# MSS_MIBSPIA register map
Vendor: Texas Instruments
Peripheral module from a debugger description file (folder radar).
Registers are 32-bit, access per field, no defined reset value unless marked. A register's access mark holds for its fields unless they carry their own. Offsets are as the file gives them; lines under a group give offsets from that group; [hi:lo] are bit positions; {n}, {i} and the like mark numbered series; 'fields as' and 'values as' point back to an identical list; <NAME> marks a mode.

## MSS_MIBSPIA (part 1 of 4)
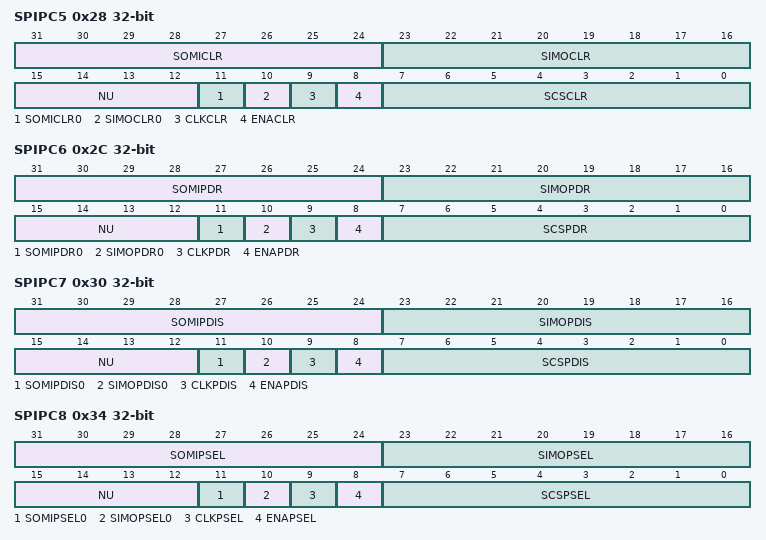
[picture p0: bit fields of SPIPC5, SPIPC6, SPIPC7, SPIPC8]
0x28 SPIPC5 — SPI / MibSPI Pin Control Register 5 (SPIPC5) - SPIDCLR
  [31:24] SOMICLR rw — SPISOMIx dataout clear. Only active when the SPISOMIx pin is configured as a general-purpose output pin. A value of ‘1’ written to this bit clears the corresponding SPISOMIDOUTx bit to ‘0’. Write: 0= Has no effect 1= Logic 0 placed on SPISOMIx pin if it is in General Purpose O/P mode Read: 0= Current value on SOMIDOUTx is 0. 1= Current value on SOMIDOUTx is 1.
  [23:16] SIMOCLR rw — SPISIMOx dataout clear. Only active when the SPISIMOx pin is configured as a general-purpose output pin. A value of ‘1’ written to this bit clears the corresponding SPISIMODOUTx bit to ‘0’. Write: 0= Has no effect 1= Logic 0 placed on SPISIMOx pin if it is in General Purpose O/P mode Read: 0=Current value on SIMODOUTx is 0. 1=Current value on SIMODOUTx is 1.
  [15:12] NU ro — Reserved. Reads return ‘0’ and writes have no effect.
  [11] SOMICLR0 rw — SPISOMI0 dataout clear. Only active when the SPISOMI0 pin is configured as a general-purpose output pin. A value of ‘1’ written to this bit clears the corresponding SPISOMIDOUT bit to ‘0’. Write: 0= Has no effect 1= Logic 0 placed on SPISOMI0 pin if it is in General Purpose O/P mode Read: 0= Current value on SOMIDOUT0 is 0. 1= Current value on SOMIDOUT0 is 1. Note: Bit 11 or bit 24 can be used to set the direction for pin SOMI0. If a 32 bit write is performed, bit 11 will have priority over bit 24.
  [10] SIMOCLR0 rw — SPISIMO0 dataout clear. Only active when the SPISIMO0 pin is configured as a general-purpose output pin. A value of ‘1’ written to this bit clears the corresponding SIMODOUT0 bit to ‘0’. Write: 0= Has no effect 1= Logic 0 placed on SPISIMO0 pin if it is in General Purpose O/P mode Read: 0= Current value on SIMODOUT0 is 0. 1= Current value on SIMODOUT0 is 1. Note: Bit 10 or bit 16 can be used to set the direction for pin SIMO0. If a 32 bit write is performed, bit 10 will have priority over bit 16.
  [9] CLKCLR rw — SPICLK dataout clear. Only active when the SPICLK pin is configured as a general-purpose output pin. A value of ‘1’ written to this bit clears the corresponding CLKDOUT bit to ‘0’. Write: 0= Has no effect 1= Logic 0 placed on SPICLK pin if it is in General Purpose O/P mode Read: 0= Current value on CLKDOUT is 0. 1= Current value on CLKDOUT is 1.
  [8] ENACLR rw — SPIENA dataout clear. Only active when the SPIENA pin is configured as a general-purpose output pin. A value of ‘1’ written to this bit clears the corresponding ENABLEDOUT bit to ‘0’. Write: 0= Has no effect 1= Logic 0 placed on SPIENA pin if it is in General Purpose O/P mode Read: 0= Current value on ENADOUT is 0. 1= Current value on ENADOUT is 1.
  [7:0] SCSCLR rw — SPISCS[7:0] dataout clear. Only active when the SPISCSx pins are configured as a general-purpose output pins. A value of ‘1’ written to this bit clears the corresponding SCSDOUT bit to ‘0.. Write: 0= Has no effect 1= Logic 0 placed on SPISCSx pin if it is in General Purpose O/P mode Read: 0= Current value on SCSDOUTx is 0. 1= Current value on SCSDOUTx is 1 Note: Effect of NUM_CS_PINS generic on ChipSelect bits. Actual number of bits implemented in SCSCLR[7:0] will depend upon the NUM_CS_PINS generic set during synthesis. Unimplemented bits will be read-only and will read ‘0’ always. Note: Register Read Read of SPIPC5 register gives out contents of the SPIPC3 register.
0x2C SPIPC6 — SPI / MibSPI Pin Control Register 6 (SPIPC6) - SPIPDR
  [31:24] SOMIPDR rw — SPISOMIx Open drain enable Enables Open drain capability for the pin SOMIx if the following conditions are met. SOMIDIRx = 1 (SPISOMI0 pin configured in GPIO mode as output pin) SOMIDOUTx = 1 0 = Output value on SPISOMIx pin is logic ‘1’ 1 = Output pin SPISOMIx is Tri-stated
  [23:16] SIMOPDR rw — SPISIMOx Open drain enable Enables Open drain capability for the pin SPISIMOx if the following conditions are met. SIMODIRx = 1 (SPISIMOx pin configured in GPIO mode as output pin) SIMODOUTx = 1 0 = Output value on SPISIMOx pin is logic ‘1’ 1 = Output pin SPISIMOx is Tri-stated
  [15:12] NU ro — Reserved. Reads return ‘0’ and writes have no effect.
  [11] SOMIPDR0 rw — SPISOMI0 Open drain enable Enables Open drain capability for the pin SPISOMI if the following conditions are met. SOMIDIR0 = 1 (SPISOMI0 pin configured in GPIO mode as output pin) SOMIDOUT0 = 1 0 = Output value on SPISOMI0 pin is logic ‘1’ 1 = Output pin SPISOMI0 is Tri-stated Note: Bit 11 or bit 24 can be used to set the direction for pin SPISOMI0. If a 32 bit write is performed, bit 11 will have priority over bit 24.
  [10] SIMOPDR0 rw — SPISIMO0 Open drain enable Enables Open drain capability for the pin SPISIMO0 if the following conditions are met. SIMODIR0 = 1 (SPISIMO pin configured in GPIO mode as output pin) SIMODOUT0 = 1 0 = Output value on SPISIMO0 pin is logic ‘1’ 1 = Output pin SPISIMO0 is Tri-stated Note: Bit 10 or bit 16 can be used to set the direction for pin SPISIMO0. If a 32 bit write is performed, bit 10 will have priority over bit 16.
  [9] CLKPDR rw — SPICLK Open drain enable Enables Open drain capability for the pin CLK if the following conditions are met. CLKDIR = 1 (SPICLK pin configured in GPIO mode as output pin) CLKDOUT = 1 0 = Output value on SPICLK pin is logic ‘1’ 1 = Output pin SPICLK is Tri-stated
  [8] ENAPDR rw — SPIENA Open drain enable Enables Open drain capability for the pin SPIENA if the following conditions are met. ENABLEDIR = 1 (SPIENA pin configured in GPIO mode as output pin) ENABLEDOUT = 1 0 = Output value on SPIENA pin is logic ‘1’ 1 = Output pin SPIENA is Tri-stated
  [7:0] SCSPDR rw — SPISCSx Open drain enable Enables Open drain capability for the pin SPISCSx if the following conditions are met. SCSDIRx = 1 (SPISCS pin configured in GPIO mode as output pin) SCSDOUTx = 1 0 = Output value on SPISCSx pin is logic ‘1’ 1 = Output pin SPISCSx is Tri-stated Note: Effect of NUM_CS_PINS generic on ChipSelect bits. Actual number of bits implemented in SCSPDR[7:0] will depend upon the NUM_CS_PINS generic set during synthesis. Unimplemented bits will be read-only and will read ‘0’ always.
0x30 SPIPC7 — SPI / MibSPI Pin Control Register 7 (SPIPC7) - SPIPDIS Note: Default Register Value. The default values of the register bits are determined by the value at the port PULDIS_TIEOFF on the SPI/MibSPI entity. This port needs to be tied-off during device integration. Default value will be same as the value of PULDIS_TIEOFF port.
  [31:24] SOMIPDIS rw — SPISOMIx Pull Control enable/disable Enables Pull Control capability for the pin SPISOMIx pin if it is in input mode irrespective of whether it is in Functional or GPIO mode. 0 = Pull control on SPISOMIx pin is enabled 1 = Pull control on SPISOMIx pin is disabled
  [23:16] SIMOPDIS rw — SPISIMOx Pull Control enable/disable Enables Pull Control capability for the pin SPISIMOx pin if it is in input mode irrespective of whether it is in Functional or GPIO mode. 0 = Pull control on SPISIMOx pin is enabled 1 = Pull control on SPISIMOx pin is disabled
  [15:12] NU ro — Reserved. Reads return ‘0’ and writes have no effect.
  [11] SOMIPDIS0 rw — SPISOMI0 Pull Control enable/disable Enables Pull Control capability for the pin SPISOMI0x pin if it is in input mode irrespective of whether it is in Functional or GPIO mode. 0 = Pull control on SPISOMI0 pin is enabled 1 = Pull control on SPISOMI0 pin is disabled Note: Bit 11 or bit 24 can be used to set the direction for pin SPISOMI0. If a 32 bit write is performed, bit 11 will have priority over bit 24.
  [10] SIMOPDIS0 rw — SPISIMO Pull Control enable/disable Enables Pull Control capability for the pin SPISIMO0x pin if it is in input mode irrespective of whether it is in Functional or GPIO mode. 0 = Pull control on SPISIMO0 pin is enabled 1 = Pull control on SPISIMO0 pin is disabled Note: Bit 10 or bit 16 can be used to set the direction for pin SPISIMO0. If a 32 bit write is performed, bit 10 will have priority over bit 16.
  [9] CLKPDIS rw — SPICLK Pull Control enable/disable Enables Pull Control capability for the pin SPICLK pin if it is in input mode irrespective of whether it is in Functional or GPIO mode. 0 = Pull control on SPICLK pin is enabled 1 = Pull control on SPICLK pin is disabled
  [8] ENAPDIS rw — SPIENA Pull Control enable/disable Enables Pull Control capability for the pin SPIENA pin if it is in input mode irrespective of whether it is in Functional or GPIO mode. 0 = Pull control on SPIENA pin is enabled 1 = Pull control on SPIENA pin is disabled
  [7:0] SCSPDIS rw — SPISCSx Pull Control enable/disable Enables Pull Control capability for the pin SPISCSx pin if it is in input mode irrespective of whether it is in Functional or GPIO mode. 0 = Pull control on SPISCSx pin is enabled 1 = Pull control on SPISCSx pin is disabled Note: Effect of NUM_CS_PINS generic on ChipSelect bits. Actual number of bits implemented in SCSPDIS[7:0] will depend upon the NUM_CS_PINS generic set during synthesis. Unimplemented bits will be read-only and will read ‘0’ always.
0x34 SPIPC8 — SPI / MibSPI Pin Control Register 8 (SPIPC8) - SPIPSEL Note: Default Register Value. The default values of this register bits are determined by the value at the port PULDIS_TIEOFF on the SPI/MibSPI entity. This port needs to be tied-off during device integration. The default value will be the inverted value of PULDIS_TIEOFF port.
  [31:24] SOMIPSEL rw — SPISOMIx Pull Select Selects type of pull logic at the SPISOMIx pin. 0 = Pull down on SPISOMIx pin 1 = Pull up on SPISOMIx pin
  [23:16] SIMOPSEL rw — SPISIMOx Pull Select Selects type of pull logic at the SPISIMOx pin. 0 = Pull down on SPISIMOx pin 1 = Pull up on SPISIMOx pin
  [15:12] NU ro — Reserved. Reads return ‘0’ and writes have no effect.
  [11] SOMIPSEL0 rw — SPISOMI Pull Select Selects type of pull logic at the SPISOMI pin. 0 = Pull down on SPISOMI pin 1 = Pull up on SPISOMI pin Note: Bit 11 or bit 24 can be used to set the direction for pin SPISOMI0. If a 32 bit write is performed, bit 11 will have priority over bit 24.
  [10] SIMOPSEL0 rw — SPISIMO Pull Select Selects type of pull logic at the SPISIMO pin. 0 = Pull down on SPISIMO pin 1 = Pull up on SPISIMO pin Note: Bit 10 or bit 16 can be used to set the direction for pin SPISIMO0. If a 32 bit write is performed, bit 10 will have priority over bit 16.
  [9] CLKPSEL rw — SPICLK Pull Select Selects type of pull logic at the SPICLK pin. 0 = Pull down on SPICLK pin 1 = Pull up on SPICLK pin
  [8] ENAPSEL rw — SPIENA Pull select Selects type of pull logic at the SPIENA pin. 0 = Pull down on SPIENA pin. 1 = Pull up on SPIENA pin.
  [7:0] SCSPSEL rw — SPISCSx Pull select Selects type of pull logic at the SPISCSx pin. 0 = Pull down on SPISCSx. 1 = Pull up on SPISCSx pin. Note: Effect of NUM_CS_PINS generic on ChipSelect bits. Actual number of bits implemented in SCSPSEL[7:0] will depend upon the NUM_CS_PINS generic set during synthesis. Unimplemented bits will be read-only and will read ‘0’ always.
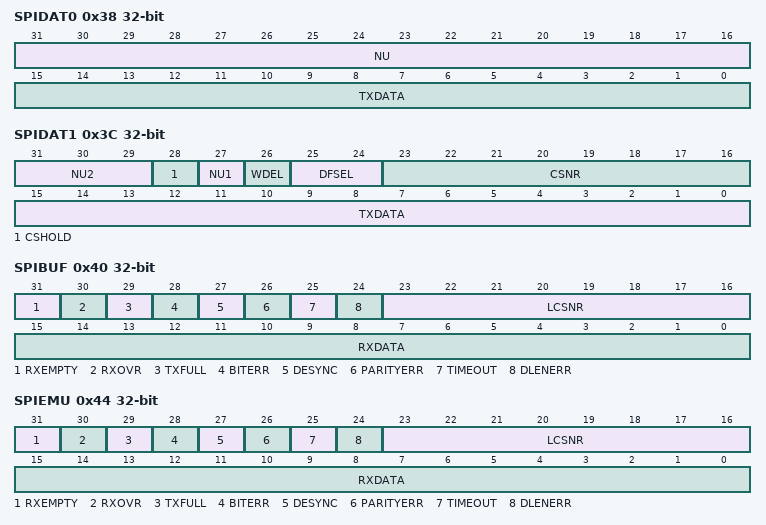
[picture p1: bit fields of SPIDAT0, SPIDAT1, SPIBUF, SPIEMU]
0x38 SPIDAT0 — SPI / MibSPI Transmit Data Register 0 Note: Accessibility of SPIDAT0 The SPIDAT0 register is not accessible in Multibuffer Mode of MibSPI. It is only accessible in compatibility mode.
  [31:16] NU ro — Reserved. Reads return ‘0’ and writes have no effect.
  [15:0] TXDATA rw — SPI / MibSPI Transmit Data. When written, these bits will be copied to the Shift Register if it is empty. If the Shift Register is not empty, the TXBUF will hold the written values. SPIEN (SPICGR1.24) must be set to 1 before this register can be written to. Writing a 0 to the SPIEN register forces the lower 16 bits of the SPIDAT0 register to 0x00. When this register is read, contents of internal buffer register TXBUF which holds the latest written data will be returned. As the data is shifted out from either the MSB or the LSB of Transmit Shift Register depending upon SHIFTDIR bit (SPIFMTx.20). Simultaneously, the received bit will be shifted into the Receive Shift Register either through LSB or MSB depending upon SHIFTDIR bit. This allows the concurrent transmission and reception of data. Note: Irrespective of the character length, the Transmit data should be right justified before writing to SPIDAT0 register. The default Data Format Control register for SPIDAT0 is SPIFMT0. However it is possible to reprogram the DFSEL[1:0] fields of SPIDAT1 prior to using SPIDAT0, to select a different SPIFMTx register.
0x3C SPIDAT1 — SPI / MibSPI Transmit Data Register 1 When this register is read, contents of internal buffer register TXBUF which holds the latest written data will be returned.
  [31:29] NU2 ro — Reserved. Reads return ‘0’ and writes have no effect.
  [28] CSHOLD rw — Chip select hold mode. In SPI or compatibility mode MibSPI, the CSHOLD bit is supported in master mode only. In slave mode, this bit is ignored. CSHOLD defines the behavior of the chip select line at the end of a data transfer. 1 =The chip select signal is held active at the end of a transfer until a control field with new data and control information is loaded into SPIDAT1. If the new chip select information equals the previous one, the active chip select signal is extended until the end of transfer with CSHOLD cleared or until the chip select information changes. 0 =The chip select signal is deactivated at the end of a transfer after the T2CDELAY time has passed. If two consecutive transfers are dedicated to the same chip select this chip select signal will be deactivated for atleast 2VCLK cycles before it is activated again.
  [27] NU1 ro — Reserved. Reads return ‘0’ and writes have no effect.
  [26] WDEL rw — Enable the delay counter at the end of the current transaction. WDELAY bit is supported in Master mode only. In Slave mode, this bit will be ignored. 1 = After a transaction, WDELAY of the corresponding data format will be loaded into the delay counter. No transaction will be performed until the WDELAY counter overflows. The SPISCS pins will be de-activated for atleast (WDELAY + 2) * VCLK_Period duration. 0 = No delay will be inserted. However, SPISCS pins will still be de-activated for atleast for 2VCLK cycles if CSHOLD = ‘0’. In SPI or Compatibility mode of MibSPI, the duration for which the SPISCS pin remaining de-activated will also depend upon time taken to supply a new data after completing the shifting operation. If the internal buffer - TXBUF is already full, then the SPISCS will be deasserted for atleast 2 VCLK cycles(if WDEL = ‘0’).
  [25:24] DFSEL rw — DFSEL1 DFSEL0 Description 0 0 Data word format 0 is selected 0 1 Data word format 1 is selected 1 0 Data word format 2 is selected 1 1 Data word format 3 is selected
  [23:16] CSNR rw — Chip select number. CSNR defines the chip select that shall be activated during the data transfer. The value of CSNR[7:0] will be driven on SPISCS[7:0] lines during the transfer. Note: Effect of NUM_CS_PINS generic on CSNR bits. Actual number of bits implemented in CSNR[7:0] will depend upon the NUM_CS_PINS generic set during synthesis. Unimplemented bits will be read-only and will read ‘0’ always. Note: Preselecting a Format Register. Writing to just the Control Field (using byte writes) does not initiate any SPI transfer in Master mode. This feature can be used to setup SPICLK Phase or Polarity before actually starting the transfer by just updating the DFSEL fields in the control field to select the required Phase/Polarity combination.
  [15:0] TXDATA rw — SPI / MibSPI Transmit Data. When written, these bits will be copied to the Shift Register if it is empty. If the Shift Register is not empty, the TXBUF will hold the written values. SPIEN must be set to 1 before this register can be written to. Writing a 0 to the SPIEN register forces the lower 16 bits of the SPIDAT1 register to 0x00. Write to this register ONLY when using the automatic Slave Chip Select feature. See section 3, Operation Modes, on page 14. A write to this register will drive the contents of CSNR[7:0] into the respective pins in SPISCS[7:0] if those are configured as functional pins. When this register is read, contents of internal buffer register TXBUF which holds the latest written data will be returned. Irrespective of the character length, the Transmit data should be right justified before writing to SPIDAT1 register.
0x40 SPIBUF access not given — SPI / MibSPI Receive Buffer Register
  [31] RXEMPTY — Receive data buffer empty. When host reads the SPIBUF field or the whole SPIBUF register this will automatically set the RXEMPTY flag. When a data transfer is completed, the received data is copied into SPIBUF, the RXEMPTY flag is cleared. 1 =No data received since last reading of SPIBUF register. 0 =A new Data is received and copied into SPIBUF field. This flag gets set to ‘1’ under following conditions: oReading RXDATA portion of the SPIBUF register. oWriting ‘1’ to clear the RXINTFLG bit in SPIFLG register. Write-Clearing the RXINTFLG bit before reading the SPIBUF indicates the received data is being ignored. Conversely, RXINTFLG can be cleared by reading the RXDATA portion of the SPIBUF register. So, reading the full of SPIBUF register itself clears the Receiver Full Interrupt Flag.
  [30] RXOVR — Receive data buffer overrun. When a data transfer is completed and the received data is copied into the RXBUF while it is already full, RXOVR is set. Refer to Figure 1 for a view of internal logic diagram. An Overrun always occurs to the RXBUF, and SPIBUF contents never get Overwritten until after it is read by the VBUSP Master. If enabled, RXOVRN interrupt gets generated when RXBUF is Overwritten, and reading SPIFLG or SPIVECTx register shows the RXOVRN condition. However, two read operations to the SPIBUF register are required to reach the Overrun buffer. 1 =A receive data overrun condition occurred since last time reading the data field. 0 =No receive data overrun condition occurred since last time reading the data field. This bit is cleared to ‘0’ under the following conditions: o RXDATA portion of the SPIBUF register is read. o OVRNINTFLG bit in SPIFLG register is write-cleared. When an Overrun occurs, the SPIBUF contents will not be overwritten. Only the RXBUF contents are overwritten. When the SPIBUF is read out , the RXBUF contents get copied to the SPIBUF if RXBUF is full. So, the first data read out will be intact when an Overrun occurs. Note: A special condition under which RXOVR flag gets set. If both SPIBUF & RXBUF are already full and while another buffer receive is underway, if any errors like TIMEOUT, BITERR & DLEN_ERR occur, then RXOVR in RXBUF & SPIFLG registers will be set to indicate that the status flags are getting overwritten by the new transfer. This overrun should be treated like a normal Receiver Overrun.
  [29] TXFULL ro — Transmit data buffer full. This flag is a read-only flag. Writing into SPIDAT0 or SPIDAT1 field while TX Shift Register is full will automatically set the TXFULL flag. Once the data is copied to the Shift Register the TXFULL flag will be cleared. Writing to SPIDAT0/SPIDAT1 register when both TXBUF & the TX Shift Register are empty does not set the TXFULL flag. 1 =Transmit buffer is full, SPIDAT0/SPIDAT1 is not ready to accept a new data. 0 =Transmit buffer is empty, SPIDAT0/SPIDAT1 is ready to accept a new data.
  [28] BITERR — Mismatch of internal transmit data and transmitted data. 1 =A bit error occurred. The SPI / MibSPI samples the signal of the transmit pin (master: SIMO, slave: SOMI) at the receive point (half clock cycle after transmit point). If the sampled value differs from the transmitted value a bit error is detected and the flag BITERR is set. A possible reason for a bit error can be noise, a to high bit rate / capacitive load or another master/slave trying to transmit at the same time. 0 =No bit error occurred. This flag is cleared to ‘0’ when RXDATA portion of the SPIBUF register is read.
  [27] DESYNC — De-synchronization of slave device. De-synchronization monitor is active in master mode only. 1 =A slave device is de-synchronized. The master monitors the ENA signal coming from the slave device and sets the DESYNC flag if ENA is deactivated before the last reception point or after the last bit is transmitted plus tT2EDELAY (see Section 8.21). If DESYNCENA is set an interrupt is asserted. De-synchronization can occur if a slave device misses a clock edge coming from the master. 0 =No slave de-synchronization detected. This bit is valid in Master mode only. This flag is cleared to ‘0’ when RXDATA portion of the SPIBUF register is read. Note: Possible inconsistency of Desync flag in SPI/Compatibility mode MibSPI Due to the nature of this Error, under some circumstances it is possible for Desync error detected for the previous buffer to be visible in the current buffer. This is due to the fact that Receive Completion flag/interrupt will be generated when the buffer transfer is completed. But Desync will be detected after the buffer transfer is completed. So, if VBUS master reads the received data quickly when an RXINT is detected, then the status flag may not reflect the correct Desync condition. This inconsistency in Desync flag is valid only in SPI or Compatibility mode of MibSPI. In Multibuffer mode, Desync flag is always guaranteed to be for the current buffer.
  [26] PARITYERR — Calculated parity differs from received parity bit. 1 =A parity error occurred. If the parity generator is enabled (can be selected individually for each buffer) an even or odd parity bit is added at the end of a data word (see Section 8.23). During reception of the data word the parity generator calculates the reference parity and compares it to the received parity bit. In the event of a mismatch the PARITYERR flag is set. 0 =No parity error detected. This flag is cleared to ‘0’ when RXDATA portion of the SPIBUF register is read.
  [25] TIMEOUT — Time-out due to non-activation of ENA pin. 1 =An ENA signal time-out occurred. The SPI / MibSPI generates a time-out because the slave hasn’t responded in time by activating the ENA signal after the chip select signal has been activated. If a time-out condition is detected the corresponding chip select is deactivated immediately and the TIMEOUT flag is set. In addition the TIMOUT flag in the status field of the corresponding buffer and in the SPIFLG register is set. 0 =No ENA-pin time-out occurred. This flag is cleared to ‘0’ when RXDATA portion of the SPIBUF register is read. This bit is valid in Master mode only.
  [24] DLENERR — Data Length Error flag. 1 = A Data Length Error has occured. 0 = No Data Length Error has occured. This flag is cleared to ‘0’ when RXDATA portion of the SPIBUF register is read.
  [23:16] LCSNR ro — Last Chip select number. LCSNR in the status field is a copy of CSNR in the corresponding control field. It defines the chip select that has been activated during the last data transfer from the corresponding buffer. This is the copy of CSNR bits from SPIDAT1 latched at the end of a transfer. Note: Effect of NUM_CS_PINS generic on LCSNR bits. Actual number of bits implemented in LCSNR[7:0] will depend upon the NUM_CS_PINS generic set during synthesis. Unimplemented bits will read ‘0’ always
  [15:0] RXDATA ro — SPI Receive Data. This is the received data, transferred from the Receive Shift-Register at the end of a transfer completion. Irrespective of the programmed character length & the direction of shifting, the received data is stored right-justified in the register.
0x44 SPIEMU ro — SPI / MibSPI Emulation Register Note: All the fields ot SPIEMU register are Read-Only. Read operation on this register under any mode will not have any impact on the status of this or any other registers.
  [31] RXEMPTY — Receive data buffer empty. 1 = No data received since last reading of SPIBUF register. 0 = A new Data is received and copied into SPIBUF field.
  [30] RXOVR — Receive data buffer overrun. 1 =A receive data overrun condition occurred since last time reading the data field. 0 =No receive data overrun condition occurred since last time reading the data field.
  [29] TXFULL — Transmit data buffer full. 1 =Transmit buffer is full, SPIDAT0/SPIDAT1 is not ready to accept a new data. 0 =Transmit buffer is empty, SPIDAT0/SPIDAT1 is ready to accept a new data.
  [28] BITERR — Mismatch of internal transmit data and transmitted data. 1 =A bit error occurred. The SPI / MibSPI samples the signal of the transmit pin (master: SIMO, slave: SOMI) at the receive point (half clock cycle after transmit point). If the sampled value differs from the transmitted value a bit error is detected and the flag BITERR is set. A possible reason for a bit error can be noise, a to high bit rate / capacitive load or another master/slave trying to transmit at the same time. 0 =No bit error occurred.
  [27] DESYNC — De-synchronization of slave device. De-synchronization monitor is active in master mode only. 1 =A slave device is de-synchronized. The master monitors the ENA signal coming from the slave device and sets the DESYNC flag if ENA is deactivated before the last reception point or after the last bit is transmitted plus tT2EDELAY (see Section 8.21). If DESYNCENA is set an interrupt is asserted. De-synchronization can occur if a slave device misses a clock edge coming from the master. 0 =No slave de-synchronization detected. This bit is valid in Master mode only.
  [26] PARITYERR — Calculated parity differs from received parity bit. 1 =A parity error occurred. If the parity generator is enabled (can be selected individually for each buffer) an even or odd parity bit is added at the end of a data word (see Section 8.23). During reception of the data word the parity generator calculates the reference parity and compares it to the received parity bit. In the event of a mismatch the PARITYERR flag is set. 0 =No parity error detected.
  [25] TIMEOUT — Time-out due to non-activation of ENA pin. 1 =An ENA signal time-out occurred. The SPI / MibSPI generates a time-out because the slave hasn’t responded in time by activating the ENA signal after the chip select signal has been activated. If a time-out condition is detected the corresponding chip select is deactivated immediately and the TIMEOUT flag is set. In addition the TIMOUT flag in the status field of the corresponding buffer and in the SPIFLG register is set. 0 =No ENA-pin time-out occurred. This bit is valid in Master mode only.
  [24] DLENERR — Data Length Error flag. 1 = A Data Length Error has occured. 0 = No Data Length Error has occured.
  [23:16] LCSNR — Last Chip select number. LCSNR in the status field is a copy of CSNR in the corresponding control field. It defines the chip select that has been activated during the last data transfer from the corresponding buffer. This is the copy of CSNR bits from SPIDAT1 latched at the end of a transfer. Note: Effect of NUM_CS_PINS generic on LCSNR bits. Actual number of bits implemented in LCSNR[7:0] will depend upon the NUM_CS_PINS generic set during synthesis. Unimplemented bits will read ‘0’ always.
  [15:0] RXDATA — SPI Receive Data. SPI / MibSPI emulation is a mirror of the SPIBUF register. The only difference between SPIEMU and SPIBUF is that a read from SPIEMU does not clear any of the status flags.
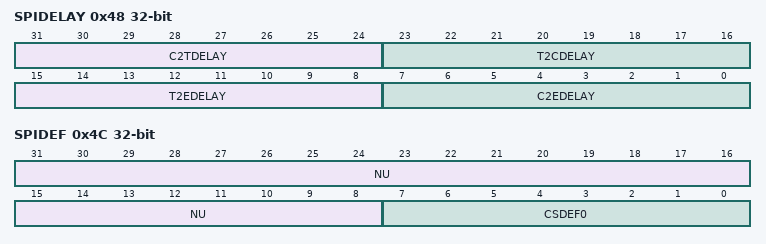
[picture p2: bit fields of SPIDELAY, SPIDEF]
0x48 SPIDELAY rw — SPI / MibSPI Delay Register
  [31:24] C2TDELAY — Chip-select-active-to-transmit-start-delay. C2TDELAY is used in master mode only. It defines a setup time for the slave device that delays the data transmission from the chip select active edge by a multiple of VBUSPCLK cycles. ChipSelect-active-to-transmission delays between 2 to 257 VBUSPCLK cycles can be achieved. If Phase = ‘1’, the delay between SCS fall-edge to the first edge of SPICLK will have an additional 0.5 SPICLK Period delay. This delay is as per the SPI protocol.
  [23:16] T2CDELAY — Transmit-end-to-chip-select-inactive-delay. T2CDELAY is used in master mode only. It defines a hold time for the slave device that delays the chip select deactivation by a multiple of VBUSPCLK cycles after the last bit is transferred. T2CDELAY can be configured between 2 and 256 VBUSPCLK cycles. If Phase = ‘0’, then between the last edge of SPICLK and rise-edge of SCS, there will be an additional delay of 0.5 SPICLK period. This is as per the SPI protocol Both C2TDELAY and T2CDELAY counters do not have any dependancy on SPIENA pin value. Even if the SPIENA pin is asserted by the Slave, Master will continue to delay the start of SPICLK until the C2TDELAY counter overflows. Similarly, even if the SPIENA pin is deasserted by the Slave, Master will continue to hold the SPISCS pins active until the T2CDELAY counter overflows. This way, it is guaranteed that the setup/hold times of the SPISCS pins is determined by the Delay timers alone. To achieve better throughput, it should be ensured that these two timers are kept at the minimum possible values.
  [15:8] T2EDELAY — Transmit-data-finished-to-ENA-pin-inactive-time-out. T2EDELAY is used in master mode only. It defines a time-out value as a multiple of SPI clock before the ENAble signal has to become inactive and after the CS becomes inactive. The SPI clock depends on which data format is selected. If the slave device is missing one or more clock edges, it is becoming de-synchronized. Although the master has finished the data transfer the slave is still waiting for the missed clock pulses and the ENA signal isn’t disabled. The T2EDELAY defines a time-out value that triggers the DESYNC flag, if the ENA signal isn’t deactivated in time. DESYNC flag is set to indicate that the Slave device did not deassert its SPIENA pin in time to acknowledge that it has received all the bits of the sent character. If T2CDELAY is programmed a non-zero value, then T2EDELAY will start only after the T2CDELAY completes. This should be taken into consideration to determine an optimum value of T2EDELAY. Note: Zero T2EDELAY If T2EDELAY is not programmed or programmed to ‘0’, then the Master SPI/MibSPI does not wait for SPIENA pin to be deasserted. It ignores the state of the SPIENA pin after the transmission is completed.
  [7:0] C2EDELAY — Chip-select-active-to-ENA-signal-active-time-out C2EDELAY is utilized only in master mode and it applies only if the addressed slave generates an ENA signal as a hardware handshake response. C2EDELAY defines the maximum time between the SPI / MibSPI activating the chip select signal and the addressed slave responding by activating the ENA signal. C2EDELAY defines a time-out value as a multiple of SPI clocks. The SPI clock depends on whether data format 0 or data format 1 is selected. If the slave device is not responding with the ENA signal before the time-out value is reached, the TIMEOUT flag in SPIFLG register is set and an interrupt is asserted if enabled. If a time-out occurs the MibSPI clears the transmit request of the timed-out buffer, sets the TIMEOUT flag for the current buffer and continues with the transfer of the next buffer in the sequence that is enabled. If C2TDELAY is programmed a non-zero value, then C2EDELAY will start only after the C2TDELAY completes. This should be taken into consideration to determine an optimum value of C2EDELAY. Note: Zero C2EDELAY If C2EDELAY is not programmed or programmed to ‘0’, then the Master SPI/MibSPI waits until the SPIENA pin to asserted before it can start the transfer. If the SPIENA pin is not asserted due to a malfunctioning Slave, the Master will wait forever. This might cause hang-up situation. it is recommended to program to C2EDELAY to a suitable value whenever SPIENA pin is used as functional.
0x4C SPIDEF — SPI / MibSPI Default Chip select Register
  [31:8] NU ro — Reserved. Reads return ‘0’ and writes have no effect.
  [7:0] CSDEF0 rw — Chip select default pattern. Master mode behavior. The CSDEFx bits are output to the chip select pins when no transmission are currently performed. It allows the user to set a chip select pattern which deselects all the SPI slaves. 1 =If CSDEFx is set to “1” the corresponding chip select is set to “1” while SPI/MibSPI is IDLE. 0 =If CSDEFx is set to “0” the corresponding chip select is set to “0” while SPI/MibSPI is IDLE. Note: Effect of NUM_CS_PINS generic on CSDEF bits. Actual number of bits implemented in CSDEF[7:0] will depend upon the NUM_CS_PINS generic set during synthesis. Unimplemented bits will be treated as reserved, read-only and will read ‘0’ always.
